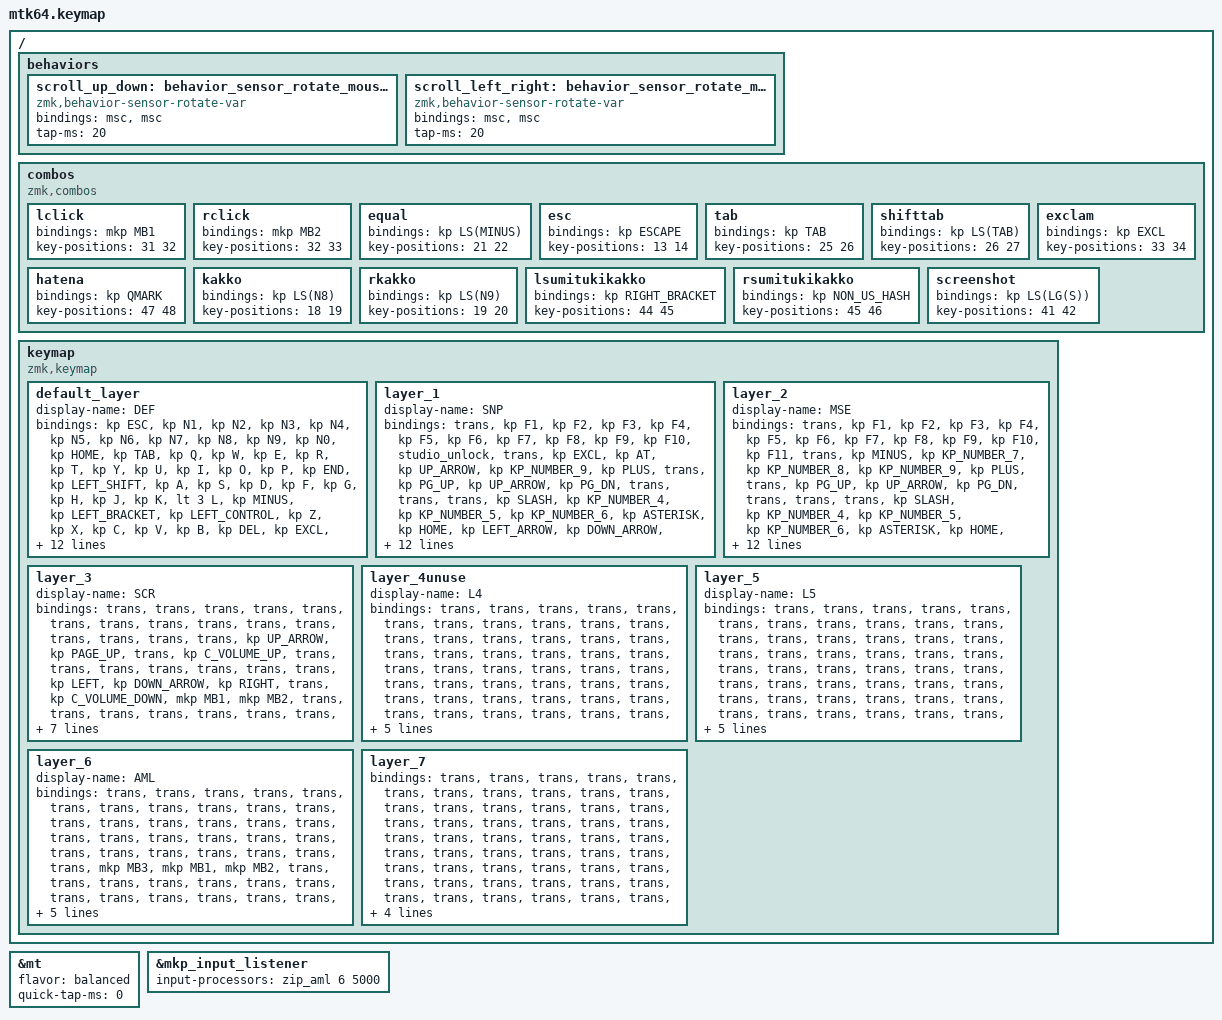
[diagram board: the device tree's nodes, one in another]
#include <input/processors.dtsi>
#include <behaviors.dtsi>
#include <dt-bindings/zmk/keys.h>
#include <dt-bindings/zmk/pointing.h>
#include "keycode_japanese.h"

// スクロール量の設定

#define ZMK_POINTING_DEFAULT_SCRL_VAL 100

&mt {
    flavor = "balanced";
    quick-tap-ms = <0>;
};

&mkp_input_listener { input-processors = <&zip_aml 6 5000>; };

/ {
    behaviors {
        // 垂直スクロール用のbehaviorの設定

        scroll_up_down: behavior_sensor_rotate_mouse_wheel_up_down {
            compatible = "zmk,behavior-sensor-rotate-var";
            #sensor-binding-cells = <2>;
            bindings = <&msc>, <&msc>;

            tap-ms = <20>; // スクロールのタップ時間
        };

        // 水平スクロール用のbehaviorの設定

        scroll_left_right: behavior_sensor_rotate_mouse_wheel_left_right {
            compatible = "zmk,behavior-sensor-rotate-var";
            #sensor-binding-cells = <2>;
            bindings = <&msc>, <&msc>;

            tap-ms = <20>; // スクロールのタップ時間
        };
    };
};

/ {
    combos {
        compatible = "zmk,combos";

        lclick {
            bindings = <&mkp MB1>;
            key-positions = <31 32>;
        };

        rclick {
            bindings = <&mkp MB2>;
            key-positions = <32 33>;
        };

        equal {
            bindings = <&kp LS(MINUS)>;
            key-positions = <21 22>;
        };

        esc {
            bindings = <&kp ESCAPE>;
            key-positions = <13 14>;
        };

        tab {
            bindings = <&kp TAB>;
            key-positions = <25 26>;
        };

        shifttab {
            bindings = <&kp LS(TAB)>;
            key-positions = <26 27>;
        };

        exclam {
            bindings = <&kp EXCL>;
            key-positions = <33 34>;
        };

        hatena {
            bindings = <&kp QMARK>;
            key-positions = <47 48>;
        };

        kakko {
            bindings = <&kp LS(N8)>;
            key-positions = <18 19>;
        };

        rkakko {
            bindings = <&kp LS(N9)>;
            key-positions = <19 20>;
        };

        lsumitukikakko {
            bindings = <&kp RIGHT_BRACKET>;
            key-positions = <44 45>;
        };

        rsumitukikakko {
            bindings = <&kp NON_US_HASH>;
            key-positions = <45 46>;
        };

        screenshot {
            bindings = <&kp LS(LG(S))>;
            key-positions = <41 42>;
        };
    };

    keymap {
        compatible = "zmk,keymap";

        default_layer {
            display-name = "DEF";
            bindings = <
&kp ESC  &kp N1  &kp N2  &kp N3  &kp N4  &kp N5  &kp N6  &kp N7  &kp N8  &kp N9  &kp N0  &kp HOME  &kp TAB  &kp Q  &kp W  &kp E  &kp R  &kp T  &kp Y  &kp U  &kp I  &kp O  &kp P  &kp END  &kp LEFT_SHIFT  &kp A  &kp S  &kp D  &kp F  &kp G  &kp H  &kp J  &kp K  &lt 3 L  &kp MINUS  &kp LEFT_BRACKET  &kp LEFT_CONTROL  &kp Z  &kp X  &kp C  &kp V  &kp B  &kp DEL  &kp EXCL  &kp N  &kp M  &kp COMMA  &kp DOT  &mt RIGHT_SHIFT SLASH  &kp RIGHT_SHIFT  &kp LALT  &kp LGUI  &lt 1 SPACE  &mt LEFT_CONTROL LANG2  &kp BSPC  &lt 1 ENTER  &kp UNDER  &kp BSLH  &trans  &trans  &mt LEFT_ALT LANG1  &mt RIGHT_SHIFT LANG_KATAKANA  &trans  &trans  &kp LC(C)  &kp LC(V)  &mo 1  &mo 2  &mo 3  &mo 1  &mo 2  &mo 3  &mo 1  &mo 2  &mo 3
            >;

            sensor-bindings = <
                &inc_dec_kp LEFT_ARROW RIGHT_ARROW
                &inc_dec_kp UP_ARROW   DOWN_ARROW
            >;
        };

        layer_1 {
            display-name = "SNP";
            bindings = <
&trans  &kp F1  &kp F2  &kp F3  &kp F4  &kp F5  &kp F6  &kp F7  &kp F8  &kp F9  &kp F10  &studio_unlock  &trans  &kp EXCL  &kp AT  &kp UP_ARROW  &kp KP_NUMBER_9  &kp PLUS  &trans  &kp PG_UP  &kp UP_ARROW  &kp PG_DN  &trans  &trans  &trans  &kp SLASH  &kp KP_NUMBER_4  &kp KP_NUMBER_5  &kp KP_NUMBER_6  &kp ASTERISK  &kp HOME  &kp LEFT_ARROW  &kp DOWN_ARROW  &kp RIGHT_ARROW  &kp END  &trans  &trans  &mt LEFT_SHIFT KP_NUMBER_0  &kp KP_NUMBER_1  &kp KP_NUMBER_2  &kp KP_NUMBER_3  &kp PERIOD  &kp EQUAL  &mkp MB4  &mkp MB5  &mkp MB1  &mkp MB2  &mkp MB3  &trans  &trans  &trans  &trans  &trans  &trans  &trans  &trans  &trans  &trans  &trans  &trans  &trans  &trans  &trans  &trans  &trans  &trans  &trans  &trans  &trans  &trans  &trans  &trans  &trans  &trans  &trans
            >;

            sensor-bindings =
                <&inc_dec_kp (LA(LC(TAB))) LA(LC(LS(TAB)))>,
                <&inc_dec_kp C_VOLUME_UP C_VOL_DN>;
        };

        layer_2 {
            display-name = "MSE";
            bindings = <
&trans  &kp F1  &kp F2  &kp F3  &kp F4  &kp F5  &kp F6  &kp F7  &kp F8  &kp F9  &kp F10  &kp F11  &trans  &kp MINUS  &kp KP_NUMBER_7  &kp KP_NUMBER_8  &kp KP_NUMBER_9  &kp PLUS  &trans  &kp PG_UP  &kp UP_ARROW  &kp PG_DN  &trans  &trans  &trans  &kp SLASH  &kp KP_NUMBER_4  &kp KP_NUMBER_5  &kp KP_NUMBER_6  &kp ASTERISK  &kp HOME  &kp LEFT_ARROW  &kp DOWN_ARROW  &kp RIGHT_ARROW  &kp END  &trans  &trans  &mt LEFT_SHIFT KP_NUMBER_0  &kp KP_NUMBER_1  &kp KP_NUMBER_2  &kp KP_NUMBER_3  &kp PERIOD  &kp EQUAL  &mkp MB4  &mkp MB5  &mkp MB1  &mkp MB2  &mkp MB3  &trans  &trans  &trans  &trans  &trans  &trans  &trans  &trans  &trans  &trans  &trans  &trans  &trans  &trans  &trans  &trans  &trans  &trans  &trans  &trans  &trans  &trans  &trans  &trans  &trans  &trans  &trans
            >;

            sensor-bindings = <
                &inc_dec_kp TAB LS(TAB) 
                &inc_dec_kp PG_UP PG_DN
            >;
        };

        layer_3 {
            display-name = "SCR";
            bindings = <
&trans  &trans  &trans  &trans  &trans  &trans  &trans  &trans  &trans  &trans  &trans  &trans  &trans  &trans  &trans  &kp UP_ARROW  &kp PAGE_UP  &trans  &kp C_VOLUME_UP  &trans  &trans  &trans  &trans  &trans  &trans  &trans  &kp LEFT  &kp DOWN_ARROW  &kp RIGHT  &trans  &kp C_VOLUME_DOWN  &mkp MB1  &mkp MB2  &trans  &trans  &trans  &trans  &trans  &trans  &trans  &kp PAGE_DOWN  &trans  &trans  &trans  &kp K_MUTE  &trans  &trans  &trans  &trans  &trans  &trans  &trans  &trans  &trans  &trans  &trans  &trans  &trans
            >;

            sensor-bindings = <
                &scroll_left_right SCRL_LEFT SCRL_RIGHT
                &scroll_up_down SCRL_UP SCRL_DOWN
            >;
        };

        layer_4unuse {
            display-name = "L4";
            bindings = <
&trans  &trans  &trans  &trans  &trans  &trans  &trans  &trans  &trans  &trans  &trans  &trans  &trans  &trans  &trans  &trans  &trans  &trans  &trans  &trans  &trans  &trans  &trans  &trans  &trans  &trans  &trans  &trans  &trans  &trans  &trans  &trans  &trans  &trans  &trans  &trans  &trans  &trans  &trans  &trans  &trans  &trans  &trans  &trans  &trans  &trans  &trans  &trans  &trans  &trans  &trans  &trans  &trans  &trans  &trans  &trans  &trans  &trans  &trans  &trans  &trans  &trans  &trans  &trans  &trans  &trans  &trans  &trans  &trans  &trans  &trans  &trans  &trans  &trans  &trans
            >;
        };

        layer_5 {
            display-name = "L5";
            bindings = <
&trans  &trans  &trans  &trans  &trans  &trans  &trans  &trans  &trans  &trans  &trans  &trans  &trans  &trans  &trans  &trans  &trans  &trans  &trans  &trans  &trans  &trans  &trans  &trans  &trans  &trans  &trans  &trans  &trans  &trans  &trans  &trans  &trans  &trans  &trans  &trans  &trans  &trans  &trans  &trans  &trans  &trans  &trans  &trans  &trans  &trans  &trans  &trans  &trans  &trans  &trans  &trans  &trans  &trans  &trans  &trans  &trans  &trans  &trans  &trans  &trans  &trans  &trans  &trans  &trans  &trans  &trans  &trans  &trans  &trans  &trans  &trans  &trans  &trans  &trans
            >;
        };

        layer_6 {
            display-name = "AML";
            bindings = <
&trans  &trans  &trans  &trans  &trans  &trans  &trans  &trans  &trans  &trans  &trans  &trans  &trans  &trans  &trans  &trans  &trans  &trans  &trans  &trans  &trans  &trans  &trans  &trans  &trans  &trans  &trans  &trans  &trans  &trans  &mkp MB3  &mkp MB1  &mkp MB2  &trans  &trans  &trans  &trans  &trans  &trans  &trans  &trans  &trans  &trans  &trans  &trans  &trans  &trans  &trans  &trans  &trans  &trans  &trans  &trans  &trans  &trans  &trans  &trans  &trans  &trans  &trans  &trans  &trans  &trans  &trans  &trans  &trans  &trans  &trans  &trans  &trans  &trans  &trans  &trans  &trans  &trans
            >;
        };

        layer_7 {
            bindings = <
&trans  &trans  &trans  &trans  &trans  &trans  &trans  &trans  &trans  &trans  &trans  &trans  &trans  &trans  &trans  &trans  &trans  &trans  &trans  &trans  &trans  &trans  &trans  &trans  &trans  &trans  &trans  &trans  &trans  &trans  &trans  &trans  &trans  &trans  &trans  &trans  &trans  &trans  &trans  &trans  &trans  &trans  &trans  &trans  &trans  &trans  &trans  &trans  &trans  &trans  &trans  &trans  &trans  &trans  &trans  &trans  &trans  &trans  &trans  &trans  &trans  &trans  &trans  &trans  &trans  &trans  &trans  &trans  &trans  &trans  &trans  &trans  &trans  &trans  &trans
            >;
        };
    };
};
